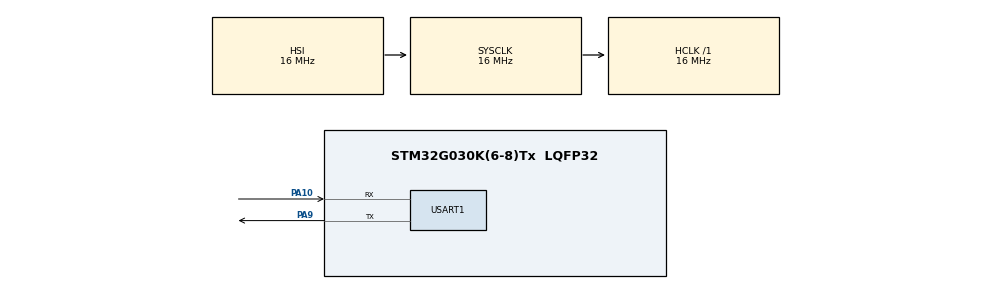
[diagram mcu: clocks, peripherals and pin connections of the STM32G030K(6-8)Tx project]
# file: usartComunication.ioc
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Mcu.Family=STM32G0
Mcu.Name=STM32G030K(6-8)Tx
Mcu.Package=LQFP32
NVIC.USART1_IRQn=true\:0\:0\:false\:false\:true\:true\:true\:true
PA10.Mode=Asynchronous
PA10.Signal=USART1_RX
PA13.Mode=Serial_Wire
PA13.Signal=SYS_SWDIO
PA14-BOOT0.Mode=Serial_Wire
PA14-BOOT0.Signal=SYS_SWCLK
PA9.Mode=Asynchronous
PA9.Signal=USART1_TX
ProjectManager.HeapSize=0x200
ProjectManager.StackSize=0x400
ProjectManager.TargetToolchain=STM32CubeIDE
RCC.AHBFreq_Value=16000000
RCC.CortexFreq_Value=16000000
RCC.EXTERNAL_CLOCK_VALUE=12288000
RCC.HCLKFreq_Value=16000000
RCC.HSE_VALUE=8000000
RCC.HSI_VALUE=16000000
RCC.LSE_VALUE=32768
RCC.SYSCLKFreq_VALUE=16000000
RCC.VCOOutputFreq_Value=128000000
USART1.VirtualMode-Asynchronous=VM_ASYNC
board=custom

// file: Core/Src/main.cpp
/* USER CODE BEGIN Header */
/**
  ******************************************************************************
  * @file           : main.c
  * @brief          : Main program body
  ******************************************************************************
  * @attention
  *
  * Copyright (c) 2025 STMicroelectronics.
  * All rights reserved.
  *
  * This software is licensed under terms that can be found in the LICENSE file
  * in the root directory of this software component.
  * If no LICENSE file comes with this software, it is provided AS-IS.
  *
  ******************************************************************************
  */
/* USER CODE END Header */
#include "main.h"

/* USER CODE BEGIN Includes */
#include "SerialUsartCommunication.h"

/* USER CODE END Includes */

UART_HandleTypeDef huart1;
/* USER CODE BEGIN PV */
SerialUsartCommunication serial(&huart1);
std::string msg = "\n\rthis is a test\n\r";
/* USER CODE END PV */

void SystemClock_Config(void);
static void MX_GPIO_Init(void);
static void MX_USART1_UART_Init(void);

int main(void)
{

  /* MCU Configuration--------------------------------------------------------*/

  /* Reset of all peripherals, Initializes the Flash interface and the Systick. */
  HAL_Init();

  /* Configure the system clock */
  SystemClock_Config();

  /* Initialize all configured peripherals */
  MX_GPIO_Init();
  MX_USART1_UART_Init();

  /* Infinite loop */
  /* USER CODE BEGIN WHILE */

  serial.recieve(5);
  while (1)
  {
	  serial.send(msg, 1);
	  HAL_Delay(1000);
	 // serial.echo();
    /* USER CODE END WHILE */

  }
}

void SystemClock_Config(void)
{
  RCC_OscInitTypeDef RCC_OscInitStruct = {0};
  RCC_ClkInitTypeDef RCC_ClkInitStruct = {0};

  /** Configure the main internal regulator output voltage
  */
  HAL_PWREx_ControlVoltageScaling(PWR_REGULATOR_VOLTAGE_SCALE1);

  /** Initializes the RCC Oscillators according to the specified parameters
  * in the RCC_OscInitTypeDef structure.
  */
  RCC_OscInitStruct.OscillatorType = RCC_OSCILLATORTYPE_HSI;
  RCC_OscInitStruct.HSIState = RCC_HSI_ON;
  RCC_OscInitStruct.HSIDiv = RCC_HSI_DIV1;
  RCC_OscInitStruct.HSICalibrationValue = RCC_HSICALIBRATION_DEFAULT;
  RCC_OscInitStruct.PLL.PLLState = RCC_PLL_NONE;
  if (HAL_RCC_OscConfig(&RCC_OscInitStruct) != HAL_OK)
  {
    Error_Handler();
  }

  /** Initializes the CPU, AHB and APB buses clocks
  */
  RCC_ClkInitStruct.ClockType = RCC_CLOCKTYPE_HCLK|RCC_CLOCKTYPE_SYSCLK
                              |RCC_CLOCKTYPE_PCLK1;
  RCC_ClkInitStruct.SYSCLKSource = RCC_SYSCLKSOURCE_HSI;
  RCC_ClkInitStruct.AHBCLKDivider = RCC_SYSCLK_DIV1;
  RCC_ClkInitStruct.APB1CLKDivider = RCC_HCLK_DIV1;

  if (HAL_RCC_ClockConfig(&RCC_ClkInitStruct, FLASH_LATENCY_0) != HAL_OK)
  {
    Error_Handler();
  }
}

static void MX_USART1_UART_Init(void)
{

  huart1.Instance = USART1;
  huart1.Init.BaudRate = 115200;
  huart1.Init.WordLength = UART_WORDLENGTH_8B;
  huart1.Init.StopBits = UART_STOPBITS_1;
  huart1.Init.Parity = UART_PARITY_NONE;
  huart1.Init.Mode = UART_MODE_TX_RX;
  huart1.Init.HwFlowCtl = UART_HWCONTROL_NONE;
  huart1.Init.OverSampling = UART_OVERSAMPLING_16;
  huart1.Init.OneBitSampling = UART_ONE_BIT_SAMPLE_DISABLE;
  huart1.Init.ClockPrescaler = UART_PRESCALER_DIV1;
  huart1.AdvancedInit.AdvFeatureInit = UART_ADVFEATURE_NO_INIT;
  if (HAL_UART_Init(&huart1) != HAL_OK)
  {
    Error_Handler();
  }
  if (HAL_UARTEx_SetTxFifoThreshold(&huart1, UART_TXFIFO_THRESHOLD_1_8) != HAL_OK)
  {
    Error_Handler();
  }
  if (HAL_UARTEx_SetRxFifoThreshold(&huart1, UART_RXFIFO_THRESHOLD_1_8) != HAL_OK)
  {
    Error_Handler();
  }
  if (HAL_UARTEx_DisableFifoMode(&huart1) != HAL_OK)
  {
    Error_Handler();
  }

}

static void MX_GPIO_Init(void)
{

  /* GPIO Ports Clock Enable */
  __HAL_RCC_GPIOA_CLK_ENABLE();

}

void Error_Handler(void)
{
  __disable_irq();
  while (1)
  {
  }
}
